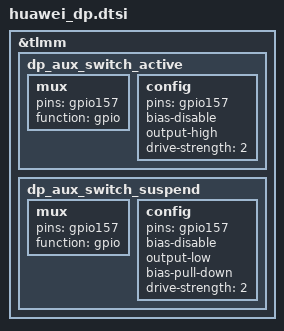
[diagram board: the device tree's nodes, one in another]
&tlmm {
	dp_aux_switch_active {
		mux {
			pins = "gpio157";
			function = "gpio";
		};

		config {
			pins = "gpio157";
			bias-disable;
			output-high;
			drive-strength = <2>; /* 2 MA */
		};
	};

	dp_aux_switch_suspend {
		mux {
			pins = "gpio157";
			function = "gpio";
		};

		config {
			pins = "gpio157";
			bias-disable;
			output-low;
			bias-pull-down; /* PULL DOWN */
			drive-strength = <2>; /* 2 MA */
		};
	};
};
